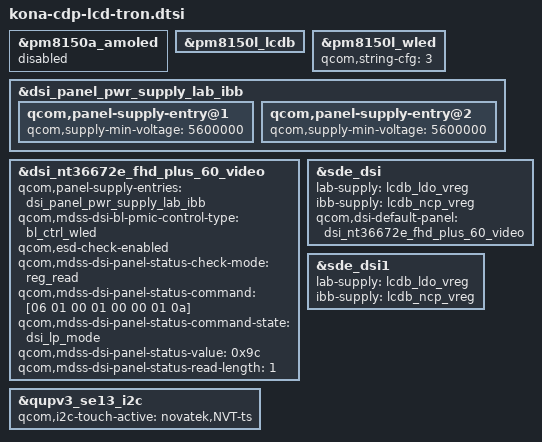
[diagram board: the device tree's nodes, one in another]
#include "kona-cdp.dtsi"

&pm8150a_amoled {
	status = "disabled";
};

&pm8150l_lcdb {
	status = "ok";
};

&pm8150l_wled {
	qcom,string-cfg = <3>;
	status = "ok";
};

&dsi_panel_pwr_supply_lab_ibb {
	qcom,panel-supply-entry@1 {
		qcom,supply-min-voltage = <5600000>;
	};

	qcom,panel-supply-entry@2 {
		qcom,supply-min-voltage = <5600000>;
	};
};

&dsi_nt36672e_fhd_plus_60_video {
	qcom,panel-supply-entries = <&dsi_panel_pwr_supply_lab_ibb>;
	qcom,mdss-dsi-bl-pmic-control-type = "bl_ctrl_wled";

	qcom,esd-check-enabled;
	qcom,mdss-dsi-panel-status-check-mode = "reg_read";
	qcom,mdss-dsi-panel-status-command = [06 01 00 01 00 00 01 0a];
	qcom,mdss-dsi-panel-status-command-state = "dsi_lp_mode";
	qcom,mdss-dsi-panel-status-value = <0x9c>;
	qcom,mdss-dsi-panel-status-read-length = <1>;
	/delete-property/ qcom,platform-en-gpio;
};

&qupv3_se13_i2c {
	qcom,i2c-touch-active = "novatek,NVT-ts";
};

&sde_dsi {
	/delete-property/ avdd-supply;
	lab-supply = <&lcdb_ldo_vreg>;
	ibb-supply = <&lcdb_ncp_vreg>;
	qcom,dsi-default-panel = <&dsi_nt36672e_fhd_plus_60_video>;
};

&sde_dsi1 {
	lab-supply = <&lcdb_ldo_vreg>;
	ibb-supply = <&lcdb_ncp_vreg>;
};
